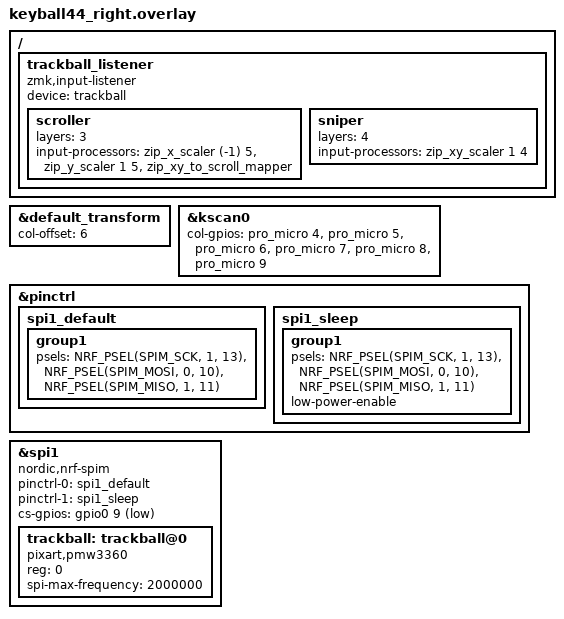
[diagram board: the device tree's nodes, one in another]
/*
 * Copyright (c) 2020 ZMK Contributors
 *
 * SPDX-License-Identifier: MIT
 */

#include "keyball44.dtsi"
#include <input/processors.dtsi>

&default_transform {
    col-offset = <6>;
};

&kscan0 {
	col-gpios
		= <&pro_micro 4 GPIO_ACTIVE_HIGH>
		, <&pro_micro 5 GPIO_ACTIVE_HIGH>
		, <&pro_micro 6 GPIO_ACTIVE_HIGH>
		, <&pro_micro 7 GPIO_ACTIVE_HIGH>
		, <&pro_micro 8 GPIO_ACTIVE_HIGH>
        , <&pro_micro 9 GPIO_ACTIVE_HIGH>
		;
};

&pinctrl {
    spi1_default: spi1_default {
        group1 {
            psels = <NRF_PSEL(SPIM_SCK, 1, 13)>,
                <NRF_PSEL(SPIM_MOSI, 0, 10)>,
                <NRF_PSEL(SPIM_MISO, 1, 11)>;
        };
    };

    spi1_sleep: spi1_sleep {
        group1 {
            psels = <NRF_PSEL(SPIM_SCK, 1, 13)>,
                <NRF_PSEL(SPIM_MOSI, 0, 10)>,
                <NRF_PSEL(SPIM_MISO, 1, 11)>;
            low-power-enable;
        };
    };
};

&spi1 {
    status = "okay";
    compatible = "nordic,nrf-spim";
    pinctrl-0 = <&spi1_default>;
    pinctrl-1 = <&spi1_sleep>;
    pinctrl-names = "default", "sleep";
    cs-gpios = <&gpio0 9 GPIO_ACTIVE_LOW>;

    trackball: trackball@0 {
        status = "okay";
        compatible = "pixart,pmw3360";
        reg = <0>;
        spi-max-frequency = <2000000>;
        /* no irq-gpios - Keyball44 PCB does not route MOTION pin, using polling */
    };
};

/ {
  trackball_listener {
    compatible = "zmk,input-listener";
    device = <&trackball>;

    /* scroll mode on layer 3 */
    scroller {
        layers = <3>;
        input-processors = <&zip_x_scaler (-1) 5>, <&zip_y_scaler 1 5>, <&zip_xy_to_scroll_mapper>;
    };

    /* snipe/precision mode on layer 4 */
    sniper {
        layers = <4>;
        input-processors = <&zip_xy_scaler 1 4>;
    };
  };
};
